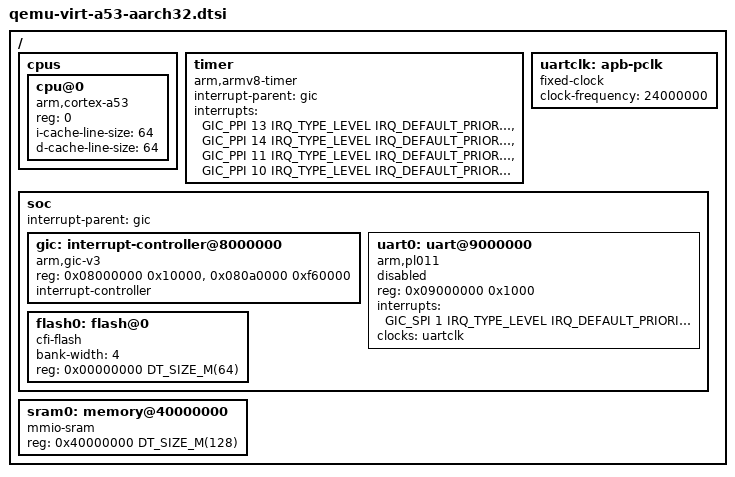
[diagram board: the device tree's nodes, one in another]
/*
 * Copyright (c) 2026 Realtek Semiconductor Corp.
 *
 * SPDX-License-Identifier: Apache-2.0
 */

#include <mem.h>
#include <arm/armv8-a.dtsi>
#include <zephyr/dt-bindings/interrupt-controller/arm-gic.h>

/ {
	#address-cells = <1>;
	#size-cells = <1>;

	cpus {
		#address-cells = <1>;
		#size-cells = <0>;

		cpu@0 {
			device_type = "cpu";
			compatible = "arm,cortex-a53";
			reg = <0>;
			i-cache-line-size = <64>;
			d-cache-line-size = <64>;
		};
	};

	timer {
		compatible = "arm,armv8-timer";
		interrupt-parent = <&gic>;
		interrupts = <GIC_PPI 13 IRQ_TYPE_LEVEL IRQ_DEFAULT_PRIORITY>,
			     <GIC_PPI 14 IRQ_TYPE_LEVEL IRQ_DEFAULT_PRIORITY>,
			     <GIC_PPI 11 IRQ_TYPE_LEVEL IRQ_DEFAULT_PRIORITY>,
			     <GIC_PPI 10 IRQ_TYPE_LEVEL IRQ_DEFAULT_PRIORITY>;
	};

	uartclk: apb-pclk {
		compatible = "fixed-clock";
		clock-frequency = <24000000>;
		#clock-cells = <0>;
	};

	soc {
		interrupt-parent = <&gic>;

		gic: interrupt-controller@8000000 {
			compatible = "arm,gic-v3", "arm,gic";
			reg = <0x08000000 0x10000>,
			      <0x080a0000 0xf60000>;
			interrupt-controller;
			#interrupt-cells = <4>;
			status = "okay";
		};

		uart0: uart@9000000 {
			compatible = "arm,pl011";
			reg = <0x09000000 0x1000>;
			interrupts = <GIC_SPI 1 IRQ_TYPE_LEVEL IRQ_DEFAULT_PRIORITY>;
			interrupt-names = "irq_0";
			clocks = <&uartclk>;
			status = "disabled";
		};

		flash0: flash@0 {
			compatible = "cfi-flash";
			bank-width = <4>;
			reg = <0x00000000 DT_SIZE_M(64)>;
		};
	};

	sram0: memory@40000000 {
		compatible = "mmio-sram";
		reg = <0x40000000 DT_SIZE_M(128)>;
	};
};
